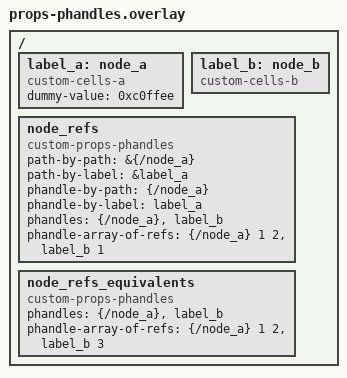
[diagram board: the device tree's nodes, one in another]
/ {
  label_a: node_a {
    compatible = "custom-cells-a";
    // The value assignment for the cells is redundant in Zephyr, since
    // the binding already specifies all names and thus the size.
    #phandle-array-of-ref-cells = <2>;
    // - name for cell 0: "name-of-cell-one"
    // - name for cell 1: "name-of-cell-two"
    dummy-value = <0xc0ffee>;
  };
  label_b: node_b {
    compatible = "custom-cells-b";
    #phandle-array-of-ref-cells = <1>;
    // - name for cell 0: "name-of-cell-one"
  };

  node_refs {
    compatible = "custom-props-phandles";

    // The type `path` exists in Zephyr, but does not lead to any usable generated output.
    // Only macros with the `_EXISTS` suffix are generated for the following nodes:
    path-by-path = &{/node_a};
    path-by-label = &label_a;

    // `phandle` types are phandle arrays with only a single entry.
    phandle-by-path = <&{/node_a}>;
    phandle-by-label = <&label_a>;

    // Simple array of phandles
    phandles = <&{/node_a} &label_b>;
    // Array of phandles _with metadata_
    phandle-array-of-refs = <&{/node_a} 1 2 &label_b 1>;
  };

  node_refs_equivalents {
    compatible = "custom-props-phandles";
    // Equivalent to `phandles = <&{/node_a} &label_b>;`
    phandles = <&{/node_a}>, <&label_b>;
    // Equivalent to `phandle-array-of-refs = <&{/node_a} 1 2 &label_b 1>;`
    phandle-array-of-refs = <&{/node_a} 1 2>, <&label_b 3>;
  };
};
